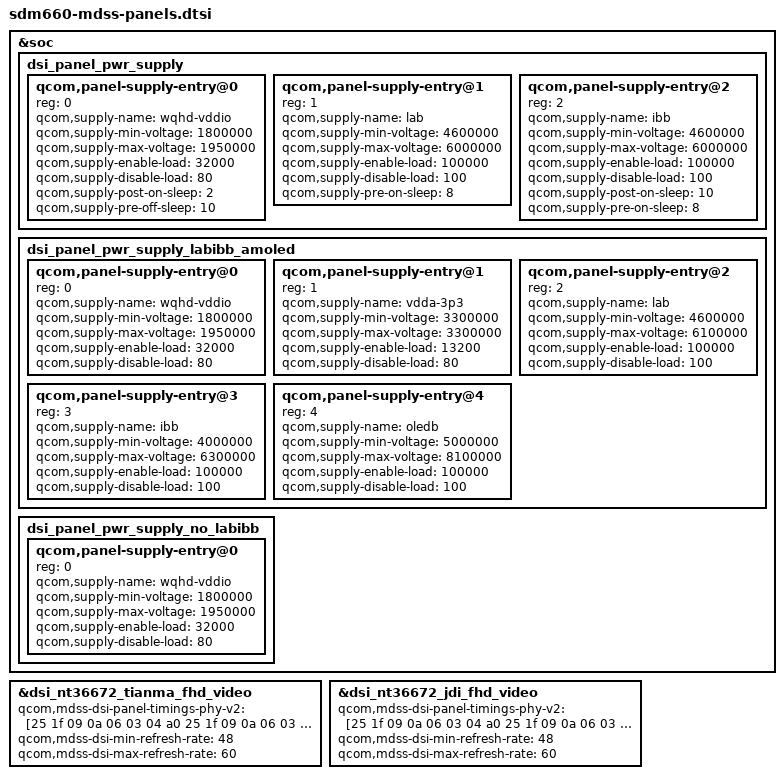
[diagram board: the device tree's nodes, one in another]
/* Copyright (c) 2016-2018, The Linux Foundation. All rights reserved.
 * Copyright (C) 2019 XiaoMi, Inc.
 *
 * This program is free software; you can redistribute it and/or modify
 * it under the terms of the GNU General Public License version 2 and
 * only version 2 as published by the Free Software Foundation.
 *
 * This program is distributed in the hope that it will be useful,
 * but WITHOUT ANY WARRANTY; without even the implied warranty of
 * MERCHANTABILITY or FITNESS FOR A PARTICULAR PURPOSE.  See the
 * GNU General Public License for more details.
 */

#include "dsi-panel-sim-video.dtsi"
#include "dsi-panel-sim-dualmipi-video.dtsi"
#include "dsi-panel-tianma-nt36672-1080p-video.dtsi"
#include "dsi-panel-jdi-nt36672-1080p-video.dtsi"

&soc {
	dsi_panel_pwr_supply: dsi_panel_pwr_supply {
		#address-cells = <1>;
		#size-cells = <0>;

		qcom,panel-supply-entry@0 {
			reg = <0>;
			qcom,supply-name = "wqhd-vddio";
			qcom,supply-min-voltage = <1800000>;
			qcom,supply-max-voltage = <1950000>;
			qcom,supply-enable-load = <32000>;
			qcom,supply-disable-load = <80>;
			qcom,supply-post-on-sleep = <2>;
			qcom,supply-pre-off-sleep = <10>;
		};

		qcom,panel-supply-entry@1 {
			reg = <1>;
			qcom,supply-name = "lab";
			qcom,supply-min-voltage = <4600000>;
			qcom,supply-max-voltage = <6000000>;
			qcom,supply-enable-load = <100000>;
			qcom,supply-disable-load = <100>;
			qcom,supply-pre-on-sleep = <8>;
		};

		qcom,panel-supply-entry@2 {
			reg = <2>;
			qcom,supply-name = "ibb";
			qcom,supply-min-voltage = <4600000>;
			qcom,supply-max-voltage = <6000000>;
			qcom,supply-enable-load = <100000>;
			qcom,supply-disable-load = <100>;
			qcom,supply-post-on-sleep = <10>;
			qcom,supply-pre-on-sleep = <8>;
		};
	};

	dsi_panel_pwr_supply_labibb_amoled:
		dsi_panel_pwr_supply_labibb_amoled {
			#address-cells = <1>;
			#size-cells = <0>;

			qcom,panel-supply-entry@0 {
				reg = <0>;
				qcom,supply-name = "wqhd-vddio";
				qcom,supply-min-voltage = <1800000>;
				qcom,supply-max-voltage = <1950000>;
				qcom,supply-enable-load = <32000>;
				qcom,supply-disable-load = <80>;
			};

			qcom,panel-supply-entry@1 {
				reg = <1>;
				qcom,supply-name = "vdda-3p3";
				qcom,supply-min-voltage = <3300000>;
				qcom,supply-max-voltage = <3300000>;
				qcom,supply-enable-load = <13200>;
				qcom,supply-disable-load = <80>;
			};

			qcom,panel-supply-entry@2 {
				reg = <2>;
				qcom,supply-name = "lab";
				qcom,supply-min-voltage = <4600000>;
				qcom,supply-max-voltage = <6100000>;
				qcom,supply-enable-load = <100000>;
				qcom,supply-disable-load = <100>;
			};

			qcom,panel-supply-entry@3 {
				reg = <3>;
				qcom,supply-name = "ibb";
				qcom,supply-min-voltage = <4000000>;
				qcom,supply-max-voltage = <6300000>;
				qcom,supply-enable-load = <100000>;
				qcom,supply-disable-load = <100>;
			};

			qcom,panel-supply-entry@4 {
				reg = <4>;
				qcom,supply-name = "oledb";
				qcom,supply-min-voltage = <5000000>;
				qcom,supply-max-voltage = <8100000>;
				qcom,supply-enable-load = <100000>;
				qcom,supply-disable-load = <100>;
			};
		};

	dsi_panel_pwr_supply_no_labibb: dsi_panel_pwr_supply_no_labibb {
		#address-cells = <1>;
		#size-cells = <0>;

		qcom,panel-supply-entry@0 {
			reg = <0>;
			qcom,supply-name = "wqhd-vddio";
			qcom,supply-min-voltage = <1800000>;
			qcom,supply-max-voltage = <1950000>;
			qcom,supply-enable-load = <32000>;
			qcom,supply-disable-load = <80>;
		};
	};
};

&dsi_nt36672_tianma_fhd_video {
	qcom,mdss-dsi-panel-timings-phy-v2 = [25 1f 09 0a 06 03 04 a0
		25 1f 09 0a 06 03 04 a0
		25 1f 09 0a 06 03 04 a0
		25 1f 09 0a 06 03 04 a0
		25 1e 08 0a 06 03 04 a0];
	qcom,mdss-dsi-min-refresh-rate = <48>;
	qcom,mdss-dsi-max-refresh-rate = <60>;
};

&dsi_nt36672_jdi_fhd_video {
	qcom,mdss-dsi-panel-timings-phy-v2 = [25 1f 09 0a 06 03 04 a0
		25 1f 09 0a 06 03 04 a0
		25 1f 09 0a 06 03 04 a0
		25 1f 09 0a 06 03 04 a0
		25 1e 08 0a 06 03 04 a0];
	qcom,mdss-dsi-min-refresh-rate = <48>;
	qcom,mdss-dsi-max-refresh-rate = <60>;
};

